VERSION ""

NS_ :

BS_:

BU_: ESC VCU CLU MDPS

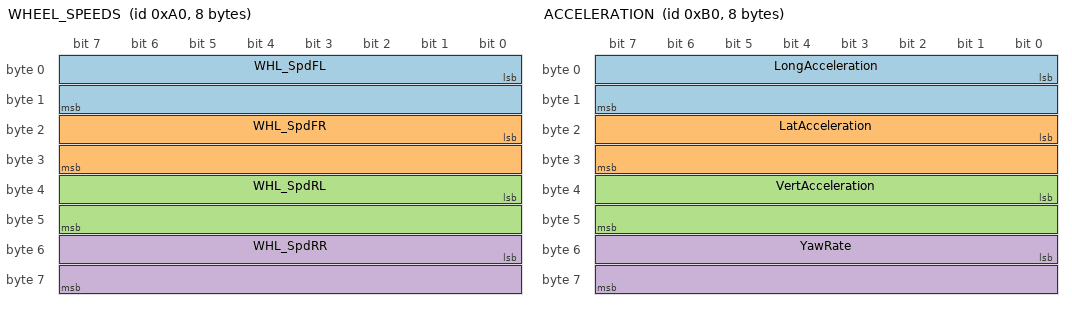
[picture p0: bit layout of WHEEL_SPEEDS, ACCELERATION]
BO_ 160 WHEEL_SPEEDS: 8 ESC
 SG_ WHL_SpdFL : 0|16@1+ (0.03125,0) [0|2047.96875] "kph" VCU,CLU
 SG_ WHL_SpdFR : 16|16@1+ (0.03125,0) [0|2047.96875] "kph" VCU,CLU
 SG_ WHL_SpdRL : 32|16@1+ (0.03125,0) [0|2047.96875] "kph" VCU,CLU
 SG_ WHL_SpdRR : 48|16@1+ (0.03125,0) [0|2047.96875] "kph" VCU,CLU

BO_ 162 WHEEL_SPEEDS_FLAGS: 8 ESC
 SG_ WHL_SpdFL_Valid : 0|1@1+ (1,0) [0|1] "" VCU,CLU
 SG_ WHL_SpdFR_Valid : 1|1@1+ (1,0) [0|1] "" VCU,CLU
 SG_ WHL_SpdRL_Valid : 2|1@1+ (1,0) [0|1] "" VCU,CLU
 SG_ WHL_SpdRR_Valid : 3|1@1+ (1,0) [0|1] "" VCU,CLU
 SG_ WHL_SpdFL_Direction : 4|2@1+ (1,0) [0|3] "" VCU
 SG_ WHL_SpdFR_Direction : 6|2@1+ (1,0) [0|3] "" VCU
 SG_ WHL_SpdRL_Direction : 8|2@1+ (1,0) [0|3] "" VCU
 SG_ WHL_SpdRR_Direction : 10|2@1+ (1,0) [0|3] "" VCU
 SG_ ABS_Active : 12|1@1+ (1,0) [0|1] "" VCU,CLU
 SG_ TCS_Active : 13|1@1+ (1,0) [0|1] "" VCU,CLU
 SG_ ESC_Active : 14|1@1+ (1,0) [0|1] "" VCU,CLU
 SG_ EPB_Status : 15|2@1+ (1,0) [0|3] "" VCU,CLU
 SG_ BrakeLight : 17|1@1+ (1,0) [0|1] "" VCU,CLU
 SG_ BrakePressed : 18|1@1+ (1,0) [0|1] "" VCU,CLU
 SG_ StandStill : 19|1@1+ (1,0) [0|1] "" VCU,CLU
 SG_ ESC_Fault : 20|1@1+ (1,0) [0|1] "" VCU,CLU
 SG_ AliveCounter : 24|4@1+ (1,0) [0|15] "" VCU
 SG_ Checksum : 28|4@1+ (1,0) [0|15] "" VCU

BO_ 176 ACCELERATION: 8 ESC
 SG_ LongAcceleration : 0|16@1+ (0.000127465,-4.17677312) [-4.17677312|4.17664566] "g" VCU,CLU
 SG_ LatAcceleration : 16|16@1+ (0.000127465,-4.17677312) [-4.17677312|4.17664566] "g" VCU,CLU
 SG_ VertAcceleration : 32|16@1+ (0.000127465,-4.17677312) [-4.17677312|4.17664566] "g" VCU
 SG_ YawRate : 48|16@1+ (0.005,-163.84) [-163.84|163.835] "deg/s" VCU,CLU

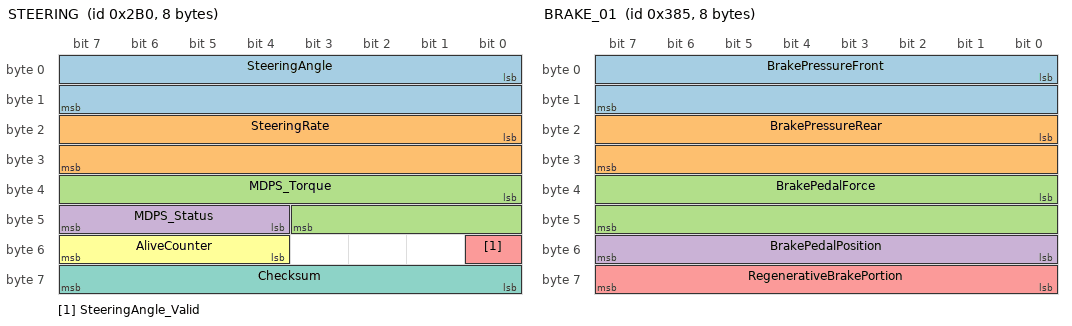
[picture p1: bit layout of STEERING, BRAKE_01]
BO_ 688 STEERING: 8 MDPS
 SG_ SteeringAngle : 0|16@1- (0.1,0) [-3276.8|3276.7] "deg" VCU,ESC,CLU
 SG_ SteeringRate : 16|16@1- (1,0) [-32768|32767] "deg/s" VCU,ESC
 SG_ MDPS_Torque : 32|12@1+ (0.1,-204.8) [-204.8|204.7] "Nm" VCU,ESC
 SG_ MDPS_Status : 44|4@1+ (1,0) [0|15] "" VCU,CLU
 SG_ SteeringAngle_Valid : 48|1@1+ (1,0) [0|1] "" VCU,ESC
 SG_ AliveCounter : 52|4@1+ (1,0) [0|15] "" VCU,ESC
 SG_ Checksum : 56|8@1+ (1,0) [0|255] "" VCU,ESC

BO_ 901 BRAKE_01: 8 ESC
 SG_ BrakePressureFront : 0|16@1+ (0.1,0) [0|6553.5] "bar" VCU
 SG_ BrakePressureRear : 16|16@1+ (0.1,0) [0|6553.5] "bar" VCU
 SG_ BrakePedalForce : 32|16@1+ (0.1,0) [0|6553.5] "N" VCU
 SG_ BrakePedalPosition : 48|8@1+ (0.390625,0) [0|99.609375] "%" VCU
 SG_ RegenerativeBrakePortion : 56|8@1+ (0.390625,0) [0|99.609375] "%" VCU,CLU

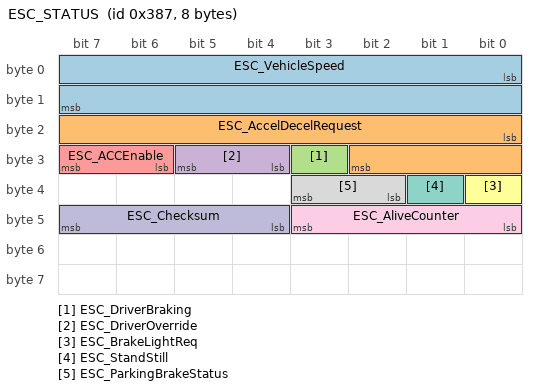
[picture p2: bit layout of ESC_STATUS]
BO_ 903 ESC_STATUS: 8 ESC
 SG_ ESC_VehicleSpeed : 0|16@1+ (0.01,0) [0|655.35] "kph" VCU,CLU
 SG_ ESC_AccelDecelRequest : 16|11@1+ (0.01,-10.23) [-10.23|10.24] "m/s^2" VCU
 SG_ ESC_DriverBraking : 27|1@1+ (1,0) [0|1] "" VCU,CLU
 SG_ ESC_DriverOverride : 28|2@1+ (1,0) [0|3] "" VCU
 SG_ ESC_ACCEnable : 30|2@1+ (1,0) [0|3] "" VCU
 SG_ ESC_BrakeLightReq : 32|1@1+ (1,0) [0|1] "" CLU
 SG_ ESC_StandStill : 33|1@1+ (1,0) [0|1] "" VCU
 SG_ ESC_ParkingBrakeStatus : 34|2@1+ (1,0) [0|3] "" VCU,CLU
 SG_ ESC_AliveCounter : 40|4@1+ (1,0) [0|15] "" VCU
 SG_ ESC_Checksum : 44|4@1+ (1,0) [0|15] "" VCU

CM_ BO_ 160 "Individual wheel speed sensors. 10ms periodic from ESC/ABS controller.";
CM_ SG_ 160 WHL_SpdFL "Front left wheel speed";
CM_ SG_ 160 WHL_SpdFR "Front right wheel speed";
CM_ SG_ 160 WHL_SpdRL "Rear left wheel speed";
CM_ SG_ 160 WHL_SpdRR "Rear right wheel speed";

CM_ BO_ 162 "Wheel speed validity flags and chassis control system status. 10ms periodic.";
CM_ SG_ 162 WHL_SpdFL_Direction "Wheel rotation direction. 0=Standstill, 1=Forward, 2=Backward, 3=Unknown";
CM_ SG_ 162 EPB_Status "Electronic Parking Brake. 0=Released, 1=Applied, 2=Applying, 3=Fault";

CM_ BO_ 176 "IMU acceleration and yaw rate. Derived from chassis IMU sensor (10ms periodic).";
CM_ SG_ 176 LongAcceleration "Longitudinal (fore-aft) acceleration. Positive = forward acceleration.";
CM_ SG_ 176 LatAcceleration "Lateral (side-to-side) acceleration. Positive = left turn acceleration.";
CM_ SG_ 176 YawRate "Vehicle yaw rate. Positive = counterclockwise (left turn) when viewed from above.";

CM_ BO_ 688 "MDPS (Motor-Driven Power Steering) status. 10ms periodic.";
CM_ SG_ 688 SteeringAngle "Steering wheel angle relative to center. Positive = left, Negative = right.";
CM_ SG_ 688 SteeringRate "Rate of change of steering wheel angle";
CM_ SG_ 688 MDPS_Torque "MDPS output torque for power assistance";
CM_ SG_ 688 MDPS_Status "0=Off, 1=Standby, 2=Normal, 3=Fault, 4=Init, 5=Reserved";

CM_ BO_ 901 "Brake system hydraulic pressures and positions. 10ms periodic.";
CM_ SG_ 901 RegenerativeBrakePortion "Proportion of total braking demand provided by regenerative braking (blended braking)";

CM_ BO_ 903 "ESC (Electronic Stability Control) comprehensive status. 10ms periodic.";
CM_ SG_ 903 ESC_AccelDecelRequest "Acceleration request from driver and/or ACC system";
CM_ SG_ 903 ESC_DriverOverride "0=No_override, 1=Throttle, 2=Brake, 3=Both";
CM_ SG_ 903 ESC_ACCEnable "0=SCC_Ready, 1=SCC_TempFault, 2=SCC_PermFault, 3=SCC_CommFault";

VAL_ 162 WHL_SpdFL_Direction 0 "Standstill" 1 "Forward" 2 "Backward" 3 "Unknown";
VAL_ 162 WHL_SpdFR_Direction 0 "Standstill" 1 "Forward" 2 "Backward" 3 "Unknown";
VAL_ 162 WHL_SpdRL_Direction 0 "Standstill" 1 "Forward" 2 "Backward" 3 "Unknown";
VAL_ 162 WHL_SpdRR_Direction 0 "Standstill" 1 "Forward" 2 "Backward" 3 "Unknown";
VAL_ 162 EPB_Status 0 "Released" 1 "Applied" 2 "Applying" 3 "Fault";
VAL_ 688 MDPS_Status 0 "Off" 1 "Standby" 2 "Normal" 3 "Fault" 4 "Init" 5 "Reserved";
VAL_ 903 ESC_DriverOverride 0 "No_Override" 1 "Throttle" 2 "Brake" 3 "Both";
VAL_ 903 ESC_ParkingBrakeStatus 0 "Released" 1 "Applied" 2 "Applying" 3 "Fault";
